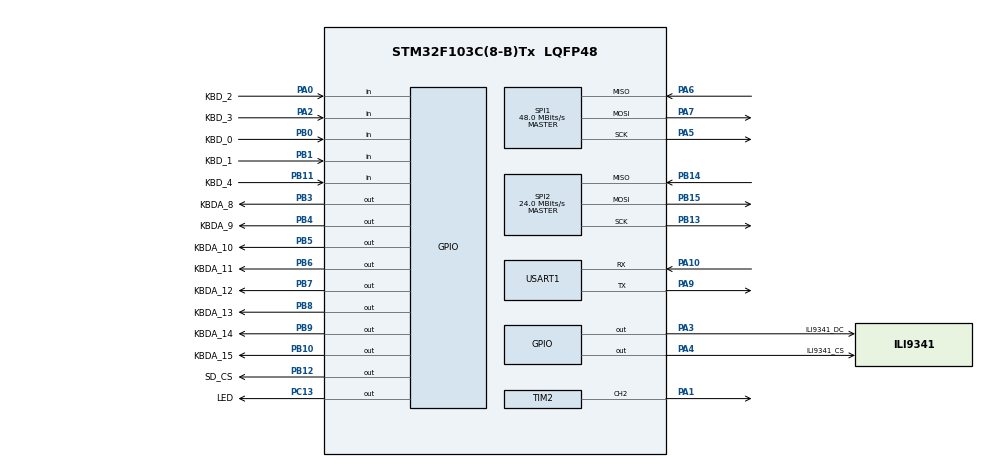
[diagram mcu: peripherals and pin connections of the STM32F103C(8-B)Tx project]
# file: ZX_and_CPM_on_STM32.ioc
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Dma.Request0=SPI1_TX
Dma.SPI1_TX.0.Direction=DMA_MEMORY_TO_PERIPH
Dma.SPI1_TX.0.Instance=DMA1_Channel3
Dma.SPI1_TX.0.MemDataAlignment=DMA_MDATAALIGN_HALFWORD
Dma.SPI1_TX.0.MemInc=DMA_MINC_ENABLE
Dma.SPI1_TX.0.Mode=DMA_NORMAL
Dma.SPI1_TX.0.PeriphDataAlignment=DMA_PDATAALIGN_HALFWORD
Dma.SPI1_TX.0.PeriphInc=DMA_PINC_DISABLE
Dma.SPI1_TX.0.Priority=DMA_PRIORITY_VERY_HIGH
FATFS._CODE_PAGE=1
FATFS._FS_MINIMIZE=1
FATFS._FS_NORTC=1
FATFS._NORTC_MDAY=1
FATFS._NORTC_MON=11
FATFS._NORTC_YEAR=2019
FATFS._USE_FASTSEEK=0
FATFS._USE_MKFS=0
FATFS._USE_STRFUNC=0
Mcu.Family=STM32F1
Mcu.Name=STM32F103C(8-B)Tx
Mcu.Package=LQFP48
NVIC.DMA1_Channel3_IRQn=true\:0\:0\:false\:false\:true\:false\:true
NVIC.PriorityGroup=NVIC_PRIORITYGROUP_4
NVIC.TIM3_IRQn=true\:0\:0\:false\:false\:true\:true\:true
PA0-WKUP.GPIO_Label=KBD_2
PA0-WKUP.GPIO_PuPd=GPIO_PULLUP
PA0-WKUP.Signal=GPIO_Input
PA1.Signal=S_TIM2_CH2
PA10.Mode=Asynchronous
PA10.Signal=USART1_RX
PA13.Mode=Serial_Wire
PA13.Signal=SYS_JTMS-SWDIO
PA14.Mode=Serial_Wire
PA14.Signal=SYS_JTCK-SWCLK
PA2.GPIO_Label=KBD_3
PA2.GPIO_PuPd=GPIO_PULLUP
PA2.Signal=GPIO_Input
PA3.GPIO_Label=ILI9341_DC
PA3.GPIO_PuPd=GPIO_PULLUP
PA3.GPIO_Speed=GPIO_SPEED_FREQ_HIGH
PA3.PinState=GPIO_PIN_SET
PA3.Signal=GPIO_Output
PA4.GPIO_Label=ILI9341_CS
PA4.GPIO_PuPd=GPIO_PULLUP
PA4.GPIO_Speed=GPIO_SPEED_FREQ_HIGH
PA4.PinState=GPIO_PIN_SET
PA4.Signal=GPIO_Output
PA5.Mode=Full_Duplex_Master
PA5.Signal=SPI1_SCK
PA6.GPIO_Mode=GPIO_MODE_INPUT
PA6.GPIO_PuPd=GPIO_NOPULL
PA6.Mode=Full_Duplex_Master
PA6.Signal=SPI1_MISO
PA7.Mode=Full_Duplex_Master
PA7.Signal=SPI1_MOSI
PA9.Mode=Asynchronous
PA9.Signal=USART1_TX
PB0.GPIO_Label=KBD_0
PB0.GPIO_PuPd=GPIO_PULLUP
PB0.Signal=GPIO_Input
PB1.GPIO_Label=KBD_1
PB1.GPIO_PuPd=GPIO_PULLUP
PB1.Signal=GPIO_Input
PB10.GPIO_Label=KBDA_15
PB10.GPIO_PuPd=GPIO_PULLUP
PB10.GPIO_Speed=GPIO_SPEED_FREQ_HIGH
PB10.PinState=GPIO_PIN_SET
PB10.Signal=GPIO_Output
PB11.GPIO_Label=KBD_4
PB11.GPIO_PuPd=GPIO_PULLUP
PB11.Signal=GPIO_Input
PB12.GPIO_Label=SD_CS
PB12.GPIO_PuPd=GPIO_PULLUP
PB12.GPIO_Speed=GPIO_SPEED_FREQ_HIGH
PB12.PinState=GPIO_PIN_SET
PB12.Signal=GPIO_Output
PB13.Mode=Full_Duplex_Master
PB13.Signal=SPI2_SCK
PB14.Mode=Full_Duplex_Master
PB14.Signal=SPI2_MISO
PB15.Mode=Full_Duplex_Master
PB15.Signal=SPI2_MOSI
PB3.GPIO_Label=KBDA_8
PB3.GPIO_PuPd=GPIO_PULLUP
PB3.GPIO_Speed=GPIO_SPEED_FREQ_HIGH
PB3.PinState=GPIO_PIN_SET
PB3.Signal=GPIO_Output
PB4.GPIO_Label=KBDA_9
PB4.GPIO_PuPd=GPIO_PULLUP
PB4.GPIO_Speed=GPIO_SPEED_FREQ_HIGH
PB4.PinState=GPIO_PIN_SET
PB4.Signal=GPIO_Output
PB5.GPIO_Label=KBDA_10
PB5.GPIO_PuPd=GPIO_PULLUP
PB5.GPIO_Speed=GPIO_SPEED_FREQ_HIGH
PB5.PinState=GPIO_PIN_SET
PB5.Signal=GPIO_Output
PB6.GPIO_Label=KBDA_11
PB6.GPIO_PuPd=GPIO_PULLUP
PB6.GPIO_Speed=GPIO_SPEED_FREQ_HIGH
PB6.PinState=GPIO_PIN_SET
PB6.Signal=GPIO_Output
PB7.GPIO_Label=KBDA_12
PB7.GPIO_PuPd=GPIO_PULLUP
PB7.GPIO_Speed=GPIO_SPEED_FREQ_HIGH
PB7.PinState=GPIO_PIN_SET
PB7.Signal=GPIO_Output
PB8.GPIO_Label=KBDA_13
PB8.GPIO_PuPd=GPIO_PULLUP
PB8.GPIO_Speed=GPIO_SPEED_FREQ_HIGH
PB8.PinState=GPIO_PIN_SET
PB8.Signal=GPIO_Output
PB9.GPIO_Label=KBDA_14
PB9.GPIO_PuPd=GPIO_PULLUP
PB9.GPIO_Speed=GPIO_SPEED_FREQ_HIGH
PB9.PinState=GPIO_PIN_SET
PB9.Signal=GPIO_Output
PC13-TAMPER-RTC.GPIO_Label=LED
PC13-TAMPER-RTC.GPIO_PuPd=GPIO_PULLUP
PC13-TAMPER-RTC.GPIO_Speed=GPIO_SPEED_FREQ_HIGH
PC13-TAMPER-RTC.PinState=GPIO_PIN_SET
PC13-TAMPER-RTC.Signal=GPIO_Output
PD0-OSC_IN.Mode=HSE-External-Oscillator
PD0-OSC_IN.Signal=RCC_OSC_IN
PD1-OSC_OUT.Mode=HSE-External-Oscillator
PD1-OSC_OUT.Signal=RCC_OSC_OUT
ProjectManager.HeapSize=0x100
ProjectManager.StackSize=0x200
ProjectManager.TargetToolchain=STM32CubeIDE
RCC.AHBFreq_Value=96000000
RCC.APB1CLKDivider=RCC_HCLK_DIV2
RCC.APB1Freq_Value=48000000
RCC.APB1TimFreq_Value=96000000
RCC.APB2Freq_Value=96000000
RCC.APB2TimFreq_Value=96000000
RCC.HCLKFreq_Value=96000000
RCC.PLLMUL=RCC_PLL_MUL12
RCC.PLLSourceVirtual=RCC_PLLSOURCE_HSE
RCC.RCC_MCOSource=RCC_MCO1SOURCE_PLLCLK
RCC.SYSCLKFreq_VALUE=96000000
RCC.SYSCLKSource=RCC_SYSCLKSOURCE_PLLCLK
RCC.USBFreq_Value=64000000
RCC.USBPrescaler=RCC_USBCLKSOURCE_PLL_DIV1_5
SH.S_TIM2_CH2.0=TIM2_CH2,PWM Generation2 CH2
SPI1.BaudRatePrescaler=SPI_BAUDRATEPRESCALER_2
SPI1.CLKPhase=SPI_PHASE_1EDGE
SPI1.CLKPolarity=SPI_POLARITY_LOW
SPI1.CalculateBaudRate=48.0 MBits/s
SPI1.DataSize=SPI_DATASIZE_8BIT
SPI1.Direction=SPI_DIRECTION_2LINES
SPI1.FirstBit=SPI_FIRSTBIT_MSB
SPI1.Mode=SPI_MODE_MASTER
SPI1.VirtualType=VM_MASTER
SPI2.BaudRatePrescaler=SPI_BAUDRATEPRESCALER_2
SPI2.CalculateBaudRate=24.0 MBits/s
SPI2.Direction=SPI_DIRECTION_2LINES
SPI2.Mode=SPI_MODE_MASTER
SPI2.VirtualType=VM_MASTER
TIM2.Channel-PWM\ Generation2\ CH2=TIM_CHANNEL_2
TIM2.Period=999
TIM2.Prescaler=95
TIM2.Pulse-PWM\ Generation2\ CH2=0
TIM3.Period=624
TIM3.Prescaler=49
USART1.VirtualMode=VM_ASYNC
VP_FATFS_VS_Generic.Mode=User_defined
VP_TIM2_VS_ClockSourceINT.Mode=Internal
VP_TIM3_VS_ClockSourceINT.Mode=Internal
board=custom

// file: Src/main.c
/* USER CODE BEGIN Header */
/**
 ******************************************************************************
 * @file           : main.c
 * @brief          : Main program body
 ******************************************************************************
 * @attention
 *
 * <h2><center>&copy; Copyright (c) 2019 STMicroelectronics.
 * All rights reserved.</center></h2>
 *
 * This software component is licensed by ST under BSD 3-Clause license,
 * the "License"; You may not use this file except in compliance with the
 * License. You may obtain a copy of the License at:
 *                        opensource.org/licenses/BSD-3-Clause
 *
 ******************************************************************************
 */
/* USER CODE END Header */

#include "main.h"
#include "fatfs.h"

/* USER CODE BEGIN Includes */
#include "mainfnc.h"
/* USER CODE END Includes */

void SystemClock_Config(void);
static void MX_GPIO_Init(void);
static void MX_DMA_Init(void);
static void MX_SPI1_Init(void);
static void MX_TIM2_Init(void);
static void MX_TIM3_Init(void);
static void MX_SPI2_Init(void);
static void MX_USART1_UART_Init(void);

int main(void)
{

  /* MCU Configuration--------------------------------------------------------*/

  /* Reset of all peripherals, Initializes the Flash interface and the Systick. */
  HAL_Init();

  /* Configure the system clock */
  SystemClock_Config();

  /* Initialize all configured peripherals */
  MX_GPIO_Init();
  MX_DMA_Init();
  MX_SPI1_Init();
  MX_TIM2_Init();
  MX_TIM3_Init();
  MX_SPI2_Init();
  MX_FATFS_Init();
  MX_USART1_UART_Init();
  /* USER CODE BEGIN 2 */
  main_init();

  /* USER CODE END 2 */

  /* Infinite loop */
  /* USER CODE BEGIN WHILE */

  	while (1) {
  		main_loop();
    /* USER CODE END WHILE */

	}
}

void SystemClock_Config(void)
{
  LL_FLASH_SetLatency(LL_FLASH_LATENCY_2);

   if(LL_FLASH_GetLatency() != LL_FLASH_LATENCY_2)
  {
    Error_Handler();
  }
  LL_RCC_HSE_Enable();

   /* Wait till HSE is ready */
  while(LL_RCC_HSE_IsReady() != 1)
  {

  }
  LL_RCC_PLL_ConfigDomain_SYS(LL_RCC_PLLSOURCE_HSE_DIV_1, LL_RCC_PLL_MUL_12);
  LL_RCC_PLL_Enable();

   /* Wait till PLL is ready */
  while(LL_RCC_PLL_IsReady() != 1)
  {

  }
  LL_RCC_SetAHBPrescaler(LL_RCC_SYSCLK_DIV_1);
  LL_RCC_SetAPB1Prescaler(LL_RCC_APB1_DIV_2);
  LL_RCC_SetAPB2Prescaler(LL_RCC_APB2_DIV_1);
  LL_RCC_SetSysClkSource(LL_RCC_SYS_CLKSOURCE_PLL);

   /* Wait till System clock is ready */
  while(LL_RCC_GetSysClkSource() != LL_RCC_SYS_CLKSOURCE_STATUS_PLL)
  {

  }
  LL_SetSystemCoreClock(96000000);
}

static void MX_SPI1_Init(void)
{

  LL_SPI_InitTypeDef SPI_InitStruct = {0};

  LL_GPIO_InitTypeDef GPIO_InitStruct = {0};

  /* Peripheral clock enable */
  LL_APB2_GRP1_EnableClock(LL_APB2_GRP1_PERIPH_SPI1);

  LL_APB2_GRP1_EnableClock(LL_APB2_GRP1_PERIPH_GPIOA);
  /**SPI1 GPIO Configuration
  PA5   ------> SPI1_SCK
  PA6   ------> SPI1_MISO
  PA7   ------> SPI1_MOSI
  */
  GPIO_InitStruct.Pin = LL_GPIO_PIN_5|LL_GPIO_PIN_7;
  GPIO_InitStruct.Mode = LL_GPIO_MODE_ALTERNATE;
  GPIO_InitStruct.Speed = LL_GPIO_SPEED_FREQ_HIGH;
  GPIO_InitStruct.OutputType = LL_GPIO_OUTPUT_PUSHPULL;
  LL_GPIO_Init(GPIOA, &GPIO_InitStruct);

  GPIO_InitStruct.Pin = LL_GPIO_PIN_6;
  GPIO_InitStruct.Mode = LL_GPIO_MODE_FLOATING;
  LL_GPIO_Init(GPIOA, &GPIO_InitStruct);

  /* SPI1 DMA Init */

  /* SPI1_TX Init */
  LL_DMA_SetDataTransferDirection(DMA1, LL_DMA_CHANNEL_3, LL_DMA_DIRECTION_MEMORY_TO_PERIPH);

  LL_DMA_SetChannelPriorityLevel(DMA1, LL_DMA_CHANNEL_3, LL_DMA_PRIORITY_VERYHIGH);

  LL_DMA_SetMode(DMA1, LL_DMA_CHANNEL_3, LL_DMA_MODE_NORMAL);

  LL_DMA_SetPeriphIncMode(DMA1, LL_DMA_CHANNEL_3, LL_DMA_PERIPH_NOINCREMENT);

  LL_DMA_SetMemoryIncMode(DMA1, LL_DMA_CHANNEL_3, LL_DMA_MEMORY_INCREMENT);

  LL_DMA_SetPeriphSize(DMA1, LL_DMA_CHANNEL_3, LL_DMA_PDATAALIGN_HALFWORD);

  LL_DMA_SetMemorySize(DMA1, LL_DMA_CHANNEL_3, LL_DMA_MDATAALIGN_HALFWORD);

  /* SPI1 parameter configuration*/
  SPI_InitStruct.TransferDirection = LL_SPI_FULL_DUPLEX;
  SPI_InitStruct.Mode = LL_SPI_MODE_MASTER;
  SPI_InitStruct.DataWidth = LL_SPI_DATAWIDTH_8BIT;
  SPI_InitStruct.ClockPolarity = LL_SPI_POLARITY_LOW;
  SPI_InitStruct.ClockPhase = LL_SPI_PHASE_1EDGE;
  SPI_InitStruct.NSS = LL_SPI_NSS_SOFT;
  SPI_InitStruct.BaudRate = LL_SPI_BAUDRATEPRESCALER_DIV2;
  SPI_InitStruct.BitOrder = LL_SPI_MSB_FIRST;
  SPI_InitStruct.CRCCalculation = LL_SPI_CRCCALCULATION_DISABLE;
  SPI_InitStruct.CRCPoly = 10;
  LL_SPI_Init(SPI1, &SPI_InitStruct);

}

static void MX_SPI2_Init(void)
{

  LL_SPI_InitTypeDef SPI_InitStruct = {0};

  LL_GPIO_InitTypeDef GPIO_InitStruct = {0};

  /* Peripheral clock enable */
  LL_APB1_GRP1_EnableClock(LL_APB1_GRP1_PERIPH_SPI2);

  LL_APB2_GRP1_EnableClock(LL_APB2_GRP1_PERIPH_GPIOB);
  /**SPI2 GPIO Configuration
  PB13   ------> SPI2_SCK
  PB14   ------> SPI2_MISO
  PB15   ------> SPI2_MOSI
  */
  GPIO_InitStruct.Pin = LL_GPIO_PIN_13|LL_GPIO_PIN_15;
  GPIO_InitStruct.Mode = LL_GPIO_MODE_ALTERNATE;
  GPIO_InitStruct.Speed = LL_GPIO_SPEED_FREQ_HIGH;
  GPIO_InitStruct.OutputType = LL_GPIO_OUTPUT_PUSHPULL;
  LL_GPIO_Init(GPIOB, &GPIO_InitStruct);

  GPIO_InitStruct.Pin = LL_GPIO_PIN_14;
  GPIO_InitStruct.Mode = LL_GPIO_MODE_FLOATING;
  LL_GPIO_Init(GPIOB, &GPIO_InitStruct);

  /* SPI2 parameter configuration*/
  SPI_InitStruct.TransferDirection = LL_SPI_FULL_DUPLEX;
  SPI_InitStruct.Mode = LL_SPI_MODE_MASTER;
  SPI_InitStruct.DataWidth = LL_SPI_DATAWIDTH_8BIT;
  SPI_InitStruct.ClockPolarity = LL_SPI_POLARITY_LOW;
  SPI_InitStruct.ClockPhase = LL_SPI_PHASE_1EDGE;
  SPI_InitStruct.NSS = LL_SPI_NSS_SOFT;
  SPI_InitStruct.BaudRate = LL_SPI_BAUDRATEPRESCALER_DIV2;
  SPI_InitStruct.BitOrder = LL_SPI_MSB_FIRST;
  SPI_InitStruct.CRCCalculation = LL_SPI_CRCCALCULATION_DISABLE;
  SPI_InitStruct.CRCPoly = 10;
  LL_SPI_Init(SPI2, &SPI_InitStruct);

}

static void MX_TIM2_Init(void)
{

  LL_TIM_InitTypeDef TIM_InitStruct = {0};
  LL_TIM_OC_InitTypeDef TIM_OC_InitStruct = {0};

  LL_GPIO_InitTypeDef GPIO_InitStruct = {0};

  /* Peripheral clock enable */
  LL_APB1_GRP1_EnableClock(LL_APB1_GRP1_PERIPH_TIM2);

  TIM_InitStruct.Prescaler = 95;
  TIM_InitStruct.CounterMode = LL_TIM_COUNTERMODE_UP;
  TIM_InitStruct.Autoreload = 999;
  TIM_InitStruct.ClockDivision = LL_TIM_CLOCKDIVISION_DIV1;
  LL_TIM_Init(TIM2, &TIM_InitStruct);
  LL_TIM_DisableARRPreload(TIM2);
  LL_TIM_SetClockSource(TIM2, LL_TIM_CLOCKSOURCE_INTERNAL);
  LL_TIM_OC_EnablePreload(TIM2, LL_TIM_CHANNEL_CH2);
  TIM_OC_InitStruct.OCMode = LL_TIM_OCMODE_PWM1;
  TIM_OC_InitStruct.OCState = LL_TIM_OCSTATE_DISABLE;
  TIM_OC_InitStruct.OCNState = LL_TIM_OCSTATE_DISABLE;
  TIM_OC_InitStruct.CompareValue = 0;
  TIM_OC_InitStruct.OCPolarity = LL_TIM_OCPOLARITY_HIGH;
  LL_TIM_OC_Init(TIM2, LL_TIM_CHANNEL_CH2, &TIM_OC_InitStruct);
  LL_TIM_OC_DisableFast(TIM2, LL_TIM_CHANNEL_CH2);
  LL_TIM_SetTriggerOutput(TIM2, LL_TIM_TRGO_RESET);
  LL_TIM_DisableMasterSlaveMode(TIM2);
  LL_APB2_GRP1_EnableClock(LL_APB2_GRP1_PERIPH_GPIOA);
  /**TIM2 GPIO Configuration
  PA1   ------> TIM2_CH2
  */
  GPIO_InitStruct.Pin = LL_GPIO_PIN_1;
  GPIO_InitStruct.Mode = LL_GPIO_MODE_ALTERNATE;
  GPIO_InitStruct.Speed = LL_GPIO_SPEED_FREQ_LOW;
  GPIO_InitStruct.OutputType = LL_GPIO_OUTPUT_PUSHPULL;
  LL_GPIO_Init(GPIOA, &GPIO_InitStruct);

}

static void MX_TIM3_Init(void)
{

  LL_TIM_InitTypeDef TIM_InitStruct = {0};

  /* Peripheral clock enable */
  LL_APB1_GRP1_EnableClock(LL_APB1_GRP1_PERIPH_TIM3);

  /* TIM3 interrupt Init */
  NVIC_SetPriority(TIM3_IRQn, NVIC_EncodePriority(NVIC_GetPriorityGrouping(),0, 0));
  NVIC_EnableIRQ(TIM3_IRQn);

  TIM_InitStruct.Prescaler = 49;
  TIM_InitStruct.CounterMode = LL_TIM_COUNTERMODE_UP;
  TIM_InitStruct.Autoreload = 624;
  TIM_InitStruct.ClockDivision = LL_TIM_CLOCKDIVISION_DIV1;
  LL_TIM_Init(TIM3, &TIM_InitStruct);
  LL_TIM_DisableARRPreload(TIM3);
  LL_TIM_SetClockSource(TIM3, LL_TIM_CLOCKSOURCE_INTERNAL);
  LL_TIM_SetTriggerOutput(TIM3, LL_TIM_TRGO_RESET);
  LL_TIM_DisableMasterSlaveMode(TIM3);

}

static void MX_USART1_UART_Init(void)
{

  LL_USART_InitTypeDef USART_InitStruct = {0};

  LL_GPIO_InitTypeDef GPIO_InitStruct = {0};

  /* Peripheral clock enable */
  LL_APB2_GRP1_EnableClock(LL_APB2_GRP1_PERIPH_USART1);

  LL_APB2_GRP1_EnableClock(LL_APB2_GRP1_PERIPH_GPIOA);
  /**USART1 GPIO Configuration
  PA9   ------> USART1_TX
  PA10   ------> USART1_RX
  */
  GPIO_InitStruct.Pin = LL_GPIO_PIN_9;
  GPIO_InitStruct.Mode = LL_GPIO_MODE_ALTERNATE;
  GPIO_InitStruct.Speed = LL_GPIO_SPEED_FREQ_HIGH;
  GPIO_InitStruct.OutputType = LL_GPIO_OUTPUT_PUSHPULL;
  LL_GPIO_Init(GPIOA, &GPIO_InitStruct);

  GPIO_InitStruct.Pin = LL_GPIO_PIN_10;
  GPIO_InitStruct.Mode = LL_GPIO_MODE_FLOATING;
  LL_GPIO_Init(GPIOA, &GPIO_InitStruct);

  USART_InitStruct.BaudRate = 115200;
  USART_InitStruct.DataWidth = LL_USART_DATAWIDTH_8B;
  USART_InitStruct.StopBits = LL_USART_STOPBITS_1;
  USART_InitStruct.Parity = LL_USART_PARITY_NONE;
  USART_InitStruct.TransferDirection = LL_USART_DIRECTION_TX_RX;
  USART_InitStruct.HardwareFlowControl = LL_USART_HWCONTROL_NONE;
  USART_InitStruct.OverSampling = LL_USART_OVERSAMPLING_16;
  LL_USART_Init(USART1, &USART_InitStruct);
  LL_USART_ConfigAsyncMode(USART1);
  LL_USART_Enable(USART1);

}

static void MX_DMA_Init(void)
{

  /* Init with LL driver */
  /* DMA controller clock enable */
  LL_AHB1_GRP1_EnableClock(LL_AHB1_GRP1_PERIPH_DMA1);

  /* DMA interrupt init */
  /* DMA1_Channel3_IRQn interrupt configuration */
  NVIC_SetPriority(DMA1_Channel3_IRQn, NVIC_EncodePriority(NVIC_GetPriorityGrouping(),0, 0));
  NVIC_EnableIRQ(DMA1_Channel3_IRQn);

}

static void MX_GPIO_Init(void)
{
  LL_GPIO_InitTypeDef GPIO_InitStruct = {0};

  /* GPIO Ports Clock Enable */
  LL_APB2_GRP1_EnableClock(LL_APB2_GRP1_PERIPH_GPIOC);
  LL_APB2_GRP1_EnableClock(LL_APB2_GRP1_PERIPH_GPIOD);
  LL_APB2_GRP1_EnableClock(LL_APB2_GRP1_PERIPH_GPIOA);
  LL_APB2_GRP1_EnableClock(LL_APB2_GRP1_PERIPH_GPIOB);

  /**/
  LL_GPIO_SetOutputPin(LED_GPIO_Port, LED_Pin);

  /**/
  LL_GPIO_SetOutputPin(GPIOA, ILI9341_DC_Pin|ILI9341_CS_Pin);

  /**/
  LL_GPIO_SetOutputPin(GPIOB, KBDA_15_Pin|SD_CS_Pin|KBDA_8_Pin|KBDA_9_Pin
                          |KBDA_10_Pin|KBDA_11_Pin|KBDA_12_Pin|KBDA_13_Pin
                          |KBDA_14_Pin);

  /**/
  GPIO_InitStruct.Pin = LED_Pin;
  GPIO_InitStruct.Mode = LL_GPIO_MODE_OUTPUT;
  GPIO_InitStruct.Speed = LL_GPIO_SPEED_FREQ_HIGH;
  GPIO_InitStruct.OutputType = LL_GPIO_OUTPUT_PUSHPULL;
  GPIO_InitStruct.Pull = LL_GPIO_PULL_UP;
  LL_GPIO_Init(LED_GPIO_Port, &GPIO_InitStruct);

  /**/
  GPIO_InitStruct.Pin = KBD_2_Pin|KBD_3_Pin;
  GPIO_InitStruct.Mode = LL_GPIO_MODE_INPUT;
  GPIO_InitStruct.Pull = LL_GPIO_PULL_UP;
  LL_GPIO_Init(GPIOA, &GPIO_InitStruct);

  /**/
  GPIO_InitStruct.Pin = ILI9341_DC_Pin|ILI9341_CS_Pin;
  GPIO_InitStruct.Mode = LL_GPIO_MODE_OUTPUT;
  GPIO_InitStruct.Speed = LL_GPIO_SPEED_FREQ_HIGH;
  GPIO_InitStruct.OutputType = LL_GPIO_OUTPUT_PUSHPULL;
  GPIO_InitStruct.Pull = LL_GPIO_PULL_UP;
  LL_GPIO_Init(GPIOA, &GPIO_InitStruct);

  /**/
  GPIO_InitStruct.Pin = KBD_0_Pin|KBD_1_Pin|KBD_4_Pin;
  GPIO_InitStruct.Mode = LL_GPIO_MODE_INPUT;
  GPIO_InitStruct.Pull = LL_GPIO_PULL_UP;
  LL_GPIO_Init(GPIOB, &GPIO_InitStruct);

  /**/
  GPIO_InitStruct.Pin = KBDA_15_Pin|SD_CS_Pin|KBDA_8_Pin|KBDA_9_Pin
                          |KBDA_10_Pin|KBDA_11_Pin|KBDA_12_Pin|KBDA_13_Pin
                          |KBDA_14_Pin;
  GPIO_InitStruct.Mode = LL_GPIO_MODE_OUTPUT;
  GPIO_InitStruct.Speed = LL_GPIO_SPEED_FREQ_HIGH;
  GPIO_InitStruct.OutputType = LL_GPIO_OUTPUT_PUSHPULL;
  GPIO_InitStruct.Pull = LL_GPIO_PULL_UP;
  LL_GPIO_Init(GPIOB, &GPIO_InitStruct);

}

void Error_Handler(void)
{
}

/************************ (C) COPYRIGHT STMicroelectronics *****END OF FILE****/
